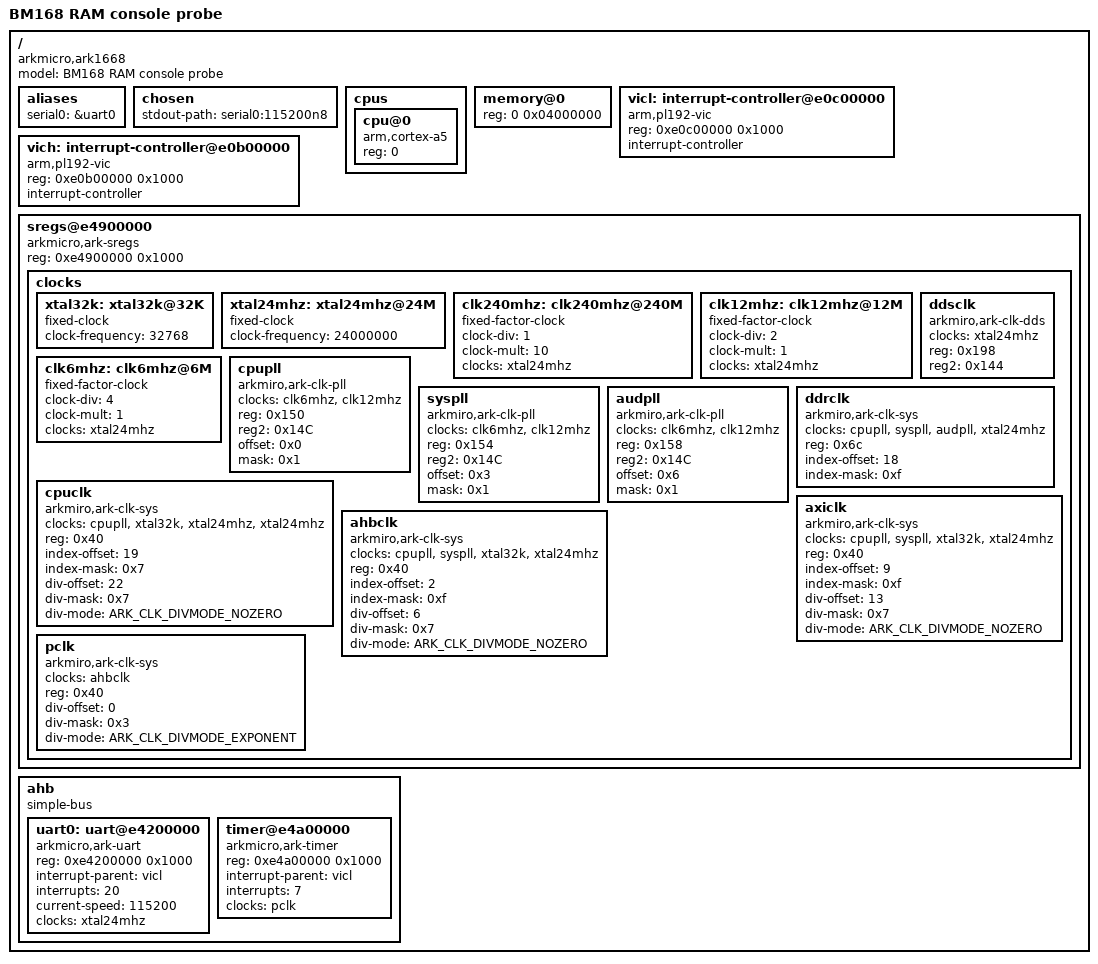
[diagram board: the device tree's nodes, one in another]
// SPDX-License-Identifier: GPL-2.0
// Minimal console candidate derived from the pinned Arkmicro SDK ark1668.dtsi.
// BM168 compatibility is unproven. No storage or MCU device is described.
/dts-v1/;
#include <dt-bindings/clock/ark-clk.h>
/ {
    #address-cells = <1>;
    #size-cells = <1>;
    model = "BM168 RAM console probe";
    compatible = "arkmicro,ark1668";
    aliases { serial0 = &uart0; };
    chosen { stdout-path = "serial0:115200n8"; };
    cpus {
        #address-cells = <1>;
        #size-cells = <0>;
        cpu@0 { device_type = "cpu"; compatible = "arm,cortex-a5"; reg = <0>; };
    };
    memory@0 { device_type = "memory"; reg = <0 0x04000000>; };
    vicl: interrupt-controller@e0c00000 {
        compatible = "arm,pl192-vic";
        reg = <0xe0c00000 0x1000>;
        interrupt-controller;
        #interrupt-cells = <1>;
    };
    vich: interrupt-controller@e0b00000 {
        compatible = "arm,pl192-vic";
        reg = <0xe0b00000 0x1000>;
        interrupt-controller;
        #interrupt-cells = <1>;
    };
	sregs@e4900000 {
		compatible = "arkmicro,ark-sregs";
		reg = <0xe4900000 0x1000>;

		clocks {
			#address-cells = <1>;
			#size-cells = <0>;

			xtal32k: xtal32k@32K {
				#clock-cells = <0>;
				compatible = "fixed-clock";
				clock-frequency = <32768>;
			};

			xtal24mhz: xtal24mhz@24M {
				#clock-cells = <0>;
				compatible = "fixed-clock";
				clock-frequency = <24000000>;
			};

			clk240mhz: clk240mhz@240M {
				#clock-cells = <0>;
				compatible = "fixed-factor-clock";
				clock-div = <1>;
				clock-mult = <10>;
				clocks = <&xtal24mhz>;
			};

			clk12mhz: clk12mhz@12M {
				#clock-cells = <0>;
				compatible = "fixed-factor-clock";
				clock-div = <2>;
				clock-mult = <1>;
				clocks = <&xtal24mhz>;
			};

			clk6mhz: clk6mhz@6M {
				#clock-cells = <0>;
				compatible = "fixed-factor-clock";
				clock-div = <4>;
				clock-mult = <1>;
				clocks = <&xtal24mhz>;
			};

			cpupll: cpupll {
				#clock-cells = <0>;
				compatible = "arkmiro,ark-clk-pll";
				clocks = <&clk6mhz>, <&clk12mhz>;
				reg = <0x150>;
				reg2 = <0x14C>;
				offset = <0x0>;
				mask = <0x1>;
			};

			syspll: syspll {
				#clock-cells = <0>;
				compatible = "arkmiro,ark-clk-pll";
				clocks = <&clk6mhz>, <&clk12mhz>;
				reg = <0x154>;
				reg2 = <0x14C>;
				offset = <0x3>;
				mask = <0x1>;
			};

			audpll: audpll {
				#clock-cells = <0>;
				compatible = "arkmiro,ark-clk-pll";
				clocks = <&clk6mhz>, <&clk12mhz>;
				reg = <0x158>;
				reg2 = <0x14C>;
				offset = <0x6>;
				mask = <0x1>;
			};

			ddsclk: ddsclk {
				#clock-cells = <0>;
				compatible = "arkmiro,ark-clk-dds";
				clocks = <&xtal24mhz>;
				reg = <0x198>;
				reg2 = <0x144>;
			};

			ddrclk: ddrclk {
				#clock-cells = <0>;
				compatible = "arkmiro,ark-clk-sys";
				clocks = <&cpupll>, <&syspll>, <&audpll>, <&xtal24mhz>;
				reg = <0x6c>;
				index-offset = <18>;
				index-mask = <0xf>;
			};

			cpuclk: cpuclk {
				#clock-cells = <0>;
				compatible = "arkmiro,ark-clk-sys";
				clocks = <&cpupll>, <&xtal32k>, <&xtal24mhz>, <&xtal24mhz>;
				reg = <0x40>;
				index-offset = <19>;
				index-mask = <0x7>;
				div-offset = <22>;
				div-mask = <0x7>;
				div-mode = <ARK_CLK_DIVMODE_NOZERO>;
			};

			axiclk: axiclk {
				#clock-cells = <0>;
				compatible = "arkmiro,ark-clk-sys";
				clocks = <&cpupll>, <&syspll>, <&xtal32k>, <&xtal24mhz>;
				reg = <0x40>;
				index-offset = <9>;
				index-mask = <0xf>;
				div-offset = <13>;
				div-mask = <0x7>;
				div-mode = <ARK_CLK_DIVMODE_NOZERO>;
			};

			ahbclk: ahbclk {
				#clock-cells = <0>;
				compatible = "arkmiro,ark-clk-sys";
				clocks = <&cpupll>, <&syspll>, <&xtal32k>, <&xtal24mhz>;
				reg = <0x40>;
				index-offset = <2>;
				index-mask = <0xf>;
				div-offset = <6>;
				div-mask = <0x7>;
				div-mode = <ARK_CLK_DIVMODE_NOZERO>;
			};

			pclk: pclk {
				#clock-cells = <0>;
				compatible = "arkmiro,ark-clk-sys";
				clocks = <&ahbclk>;
				reg = <0x40>;
				div-offset = <0>;
				div-mask = <0x3>;
				div-mode = <ARK_CLK_DIVMODE_EXPONENT>;
			};

        };
    };
    ahb {
        compatible = "simple-bus";
        #address-cells = <1>;
        #size-cells = <1>;
        ranges;
        uart0: uart@e4200000 {
            compatible = "arkmicro,ark-uart";
            reg = <0xe4200000 0x1000>;
            interrupt-parent = <&vicl>;
            interrupts = <20>;
            current-speed = <115200>;
            clocks = <&xtal24mhz>;
        };
        timer@e4a00000 {
            compatible = "arkmicro,ark-timer";
            reg = <0xe4a00000 0x1000>;
            interrupt-parent = <&vicl>;
            interrupts = <7>;
            clocks = <&pclk>;
        };
    };
};
